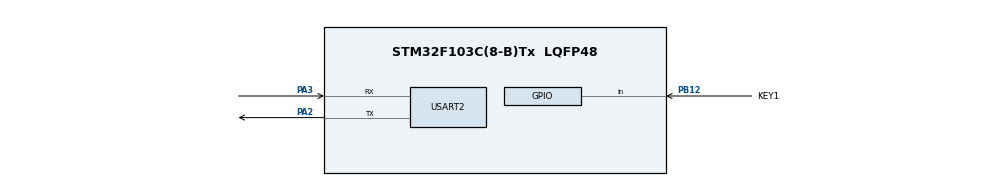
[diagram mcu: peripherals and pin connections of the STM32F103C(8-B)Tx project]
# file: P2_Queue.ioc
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FREERTOS.Queues01=BtnQueue,16,uint32_t,0,Dynamic,NULL,NULL
FREERTOS.Tasks01=BtnTask,24,128,StartBtnTask,Default,NULL,Dynamic,NULL,NULL;DataTask,8,128,StartDataTask,Default,NULL,Dynamic,NULL,NULL
Mcu.Family=STM32F1
Mcu.Name=STM32F103C(8-B)Tx
Mcu.Package=LQFP48
NVIC.PriorityGroup=NVIC_PRIORITYGROUP_4
NVIC.TIM4_IRQn=true\:15\:0\:false\:false\:true\:false\:false\:true\:true
NVIC.TimeBase=TIM4_IRQn
NVIC.TimeBaseIP=TIM4
PA13.Mode=Serial_Wire
PA13.Signal=SYS_JTMS-SWDIO
PA14.Mode=Serial_Wire
PA14.Signal=SYS_JTCK-SWCLK
PA2.Mode=Asynchronous
PA2.Signal=USART2_TX
PA3.Mode=Asynchronous
PA3.Signal=USART2_RX
PB12.GPIO_Label=KEY1
PB12.Signal=GPIO_Input
PD0-OSC_IN.Mode=HSE-External-Oscillator
PD0-OSC_IN.Signal=RCC_OSC_IN
PD1-OSC_OUT.Mode=HSE-External-Oscillator
PD1-OSC_OUT.Signal=RCC_OSC_OUT
ProjectManager.HeapSize=0x200
ProjectManager.StackSize=0x400
ProjectManager.TargetToolchain=CMake
RCC.APB1Freq_Value=8000000
RCC.APB2Freq_Value=8000000
USART2.VirtualMode=VM_ASYNC
VP_FREERTOS_VS_CMSIS_V2.Mode=CMSIS_V2
VP_SYS_VS_tim4.Mode=TIM4
board=custom

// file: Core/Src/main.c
/* USER CODE BEGIN Header */
/**
  ******************************************************************************
  * @file           : main.c
  * @brief          : Main program body
  ******************************************************************************
  * @attention
  *
  * Copyright (c) 2025 STMicroelectronics.
  * All rights reserved.
  *
  * This software is licensed under terms that can be found in the LICENSE file
  * in the root directory of this software component.
  * If no LICENSE file comes with this software, it is provided AS-IS.
  *
  ******************************************************************************
  */
/* USER CODE END Header */
#include "main.h"
#include "cmsis_os.h"
#include "usart.h"
#include "gpio.h"

void SystemClock_Config(void);
void MX_FREERTOS_Init(void);

int main(void)
{

  /* MCU Configuration--------------------------------------------------------*/

  /* Reset of all peripherals, Initializes the Flash interface and the Systick. */
  HAL_Init();

  /* Configure the system clock */
  SystemClock_Config();

  /* Initialize all configured peripherals */
  MX_GPIO_Init();
  MX_USART2_UART_Init();

  /* Init scheduler */
  osKernelInitialize();  /* Call init function for freertos objects (in cmsis_os2.c) */
  MX_FREERTOS_Init();

  /* Start scheduler */
  osKernelStart();

  /* We should never get here as control is now taken by the scheduler */

  /* Infinite loop */
  while (1)
  {

  }
}

void SystemClock_Config(void)
{
  RCC_OscInitTypeDef RCC_OscInitStruct = {0};
  RCC_ClkInitTypeDef RCC_ClkInitStruct = {0};

  /** Initializes the RCC Oscillators according to the specified parameters
  * in the RCC_OscInitTypeDef structure.
  */
  RCC_OscInitStruct.OscillatorType = RCC_OSCILLATORTYPE_HSI;
  RCC_OscInitStruct.HSIState = RCC_HSI_ON;
  RCC_OscInitStruct.HSICalibrationValue = RCC_HSICALIBRATION_DEFAULT;
  RCC_OscInitStruct.PLL.PLLState = RCC_PLL_NONE;
  if (HAL_RCC_OscConfig(&RCC_OscInitStruct) != HAL_OK)
  {
    Error_Handler();
  }

  /** Initializes the CPU, AHB and APB buses clocks
  */
  RCC_ClkInitStruct.ClockType = RCC_CLOCKTYPE_HCLK|RCC_CLOCKTYPE_SYSCLK
                              |RCC_CLOCKTYPE_PCLK1|RCC_CLOCKTYPE_PCLK2;
  RCC_ClkInitStruct.SYSCLKSource = RCC_SYSCLKSOURCE_HSI;
  RCC_ClkInitStruct.AHBCLKDivider = RCC_SYSCLK_DIV1;
  RCC_ClkInitStruct.APB1CLKDivider = RCC_HCLK_DIV1;
  RCC_ClkInitStruct.APB2CLKDivider = RCC_HCLK_DIV1;

  if (HAL_RCC_ClockConfig(&RCC_ClkInitStruct, FLASH_LATENCY_0) != HAL_OK)
  {
    Error_Handler();
  }
}

void HAL_TIM_PeriodElapsedCallback(TIM_HandleTypeDef *htim)
{
  if (htim->Instance == TIM4)
  {
    HAL_IncTick();
  }
}

void Error_Handler(void)
{
  __disable_irq();
  while (1)
  {
  }
}

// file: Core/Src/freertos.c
/* USER CODE BEGIN Header */
/**
  ******************************************************************************
  * File Name          : freertos.c
  * Description        : Code for freertos applications
  ******************************************************************************
  * @attention
  *
  * Copyright (c) 2025 STMicroelectronics.
  * All rights reserved.
  *
  * This software is licensed under terms that can be found in the LICENSE file
  * in the root directory of this software component.
  * If no LICENSE file comes with this software, it is provided AS-IS.
  *
  ******************************************************************************
  */
/* USER CODE END Header */

#include <stdio.h>
#include <string.h>

#include "FreeRTOS.h"
#include "task.h"
#include "main.h"
#include "cmsis_os.h"
#include "usart.h"

/* Definitions for BtnTask */
osThreadId_t BtnTaskHandle;
const osThreadAttr_t BtnTask_attributes = {
  .name = "BtnTask",
  .stack_size = 128 * 4,
  .priority = (osPriority_t) osPriorityNormal,
};
/* Definitions for DataTask */
osThreadId_t DataTaskHandle;
const osThreadAttr_t DataTask_attributes = {
  .name = "DataTask",
  .stack_size = 128 * 4,
  .priority = (osPriority_t) osPriorityLow,
};
/* Definitions for BtnQueue */
osMessageQueueId_t BtnQueueHandle;
const osMessageQueueAttr_t BtnQueue_attributes = {
  .name = "BtnQueue"
};

void StartBtnTask(void *argument);
void StartDataTask(void *argument);

void MX_FREERTOS_Init(void); /* (MISRA C 2004 rule 8.1) */

void MX_FREERTOS_Init(void) {

  /* Create the queue(s) */
  /* creation of BtnQueue */
  BtnQueueHandle = osMessageQueueNew (16, sizeof(uint32_t), &BtnQueue_attributes);

  /* Create the thread(s) */
  /* creation of BtnTask */
  BtnTaskHandle = osThreadNew(StartBtnTask, NULL, &BtnTask_attributes);

  /* creation of DataTask */
  DataTaskHandle = osThreadNew(StartDataTask, NULL, &DataTask_attributes);

}

void StartBtnTask(void *argument)
{
  /* USER CODE BEGIN StartBtnTask */
  uint32_t btnCount = 0;
  /* Infinite loop */
  for(;;)
  {
    if (HAL_GPIO_ReadPin(KEY1_GPIO_Port, KEY1_Pin) == GPIO_PIN_RESET) {
      osDelay(10);
      if (HAL_GPIO_ReadPin(KEY1_GPIO_Port, KEY1_Pin) == GPIO_PIN_RESET) {
        btnCount++;
        osMessageQueuePut(BtnQueueHandle, &btnCount, 0, 0);
      }while (HAL_GPIO_ReadPin(KEY1_GPIO_Port, KEY1_Pin) == GPIO_PIN_RESET)
      {
        osDelay(10);
      }
    }else {

      osDelay(10);
    }

  }
  /* USER CODE END StartBtnTask */
}

void StartDataTask(void *argument)
{
  /* USER CODE BEGIN StartDataTask */
  uint32_t datacount = 0;
  char msg[50];
  /* Infinite loop */
  for(;;)
  {
      uint32_t btnCount;
      osMessageQueueGet(BtnQueueHandle, &btnCount, NULL, osWaitForever);
      datacount++;
      osDelay(1000);
      sprintf(msg, "按键：%d次，数据：%d次\r\n",(int)btnCount,(int)datacount);
      HAL_UART_Transmit(&huart2, (uint8_t *)msg, strlen(msg), HAL_MAX_DELAY);
    }
}
  /* USER CODE END StartDataTask */
